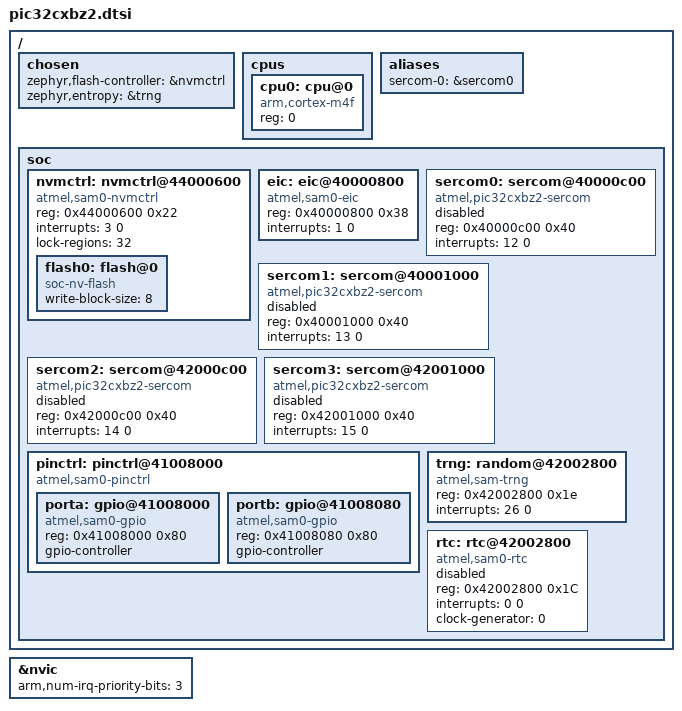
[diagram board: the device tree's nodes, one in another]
/*
 * Copyright (c) 2024 Microchip
 *
 * SPDX-License-Identifier: Apache-2.0
 */

#include <arm/armv7-m.dtsi>
#include <zephyr/dt-bindings/adc/adc.h>
#include <zephyr/dt-bindings/gpio/gpio.h>
#include <zephyr/dt-bindings/i2c/i2c.h>
#include <zephyr/dt-bindings/pwm/pwm.h>

/ {
	chosen {
		zephyr,flash-controller = &nvmctrl;
	};

	cpus {
		#address-cells = <1>;
		#size-cells = <0>;

		cpu0: cpu@0 {
			device_type = "cpu";
			compatible = "arm,cortex-m4f";
			reg = <0>;
			#address-cells = <1>;
			#size-cells = <1>;

			/*mpu: mpu@e000ed90 {
				compatible = "arm,armv7m-mpu";
				reg = <0xe000ed90 0x40>;
			};*/
		};
	};

	aliases {
		/*adc-0 = &adc0;
		

		port-a = &porta;
		port-b = &portb;*/

		sercom-0 = &sercom0;
		/*sercom-1 = &sercom1;
		sercom-2 = &sercom2;
		sercom-3 = &sercom3;

		tc-0 = &tc0;
		tc-2 = &tc2;

		tcc-0 = &tcc0;
		tcc-1 = &tcc1;
		tcc-2 = &tcc2;

		watchdog0 = &wdog;*/
	};

	chosen {
		zephyr,entropy = &trng;
	};

	soc {
		/*sram0: memory@20000000 {
			compatible = "mmio-sram";
			reg = <0x20000000 0x20000>;
		};*/

		/*backup0: memory@44014000 {44014000
			compatible = "mmio-sram";
			reg = <0x444014000 0x2000>;
		};*/

		/*id: device_id@8061fc {
			compatible = "atmel,sam0-id";
			reg =	<0x008061FC 0x4>,
				<0x00806010 0x4>,
				<0x00806014 0x4>,
				<0x00806018 0x4>;
		};*/


		nvmctrl: nvmctrl@44000600  {
			compatible = "atmel,sam0-nvmctrl";
			reg = <0x44000600 0x22>;
			interrupts = <3 0>;
			lock-regions = <32>;

			#address-cells = <1>;
			#size-cells = <1>;

			flash0: flash@0 {
				compatible = "soc-nv-flash";
				write-block-size = <8>;
			};
		};
/*
		dmac: dmac@41004000 {
			compatible = "atmel,sam0-dmac";
			reg = <0x41004000 0x50>;
			interrupts = <6 0>, <7 0>;
			#dma-cells = <2>;
		};
*/
		eic: eic@40000800 {
			compatible = "atmel,sam0-eic";
			reg = <0x40000800 0x38>;
			interrupts = <1 0>;
		};
		
/*
		pinmux_a: pinmux@41008000 {
			compatible = "atmel,sam0-pinmux";
			reg = <0x41008000 0x80>;
		};

		pinmux_b: pinmux@41008080 {
			compatible = "atmel,sam0-pinmux";
			reg = <0x41008080 0x80>;
		};

		pinmux_c: pinmux@41008100 {
			compatible = "atmel,sam0-pinmux";
			reg = <0x41008100 0x80>;
		};

		pinmux_d: pinmux@41008180 {
			compatible = "atmel,sam0-pinmux";
			reg = <0x41008180 0x80>;
		};

		wdog: watchdog@44000500{
			compatible = "atmel,sam0-watchdog";
			reg = <0x44000500 13>;
			interrupts = <140 0>;    
		};
*/

		sercom0: sercom@40000c00 {
			compatible = "atmel,pic32cxbz2-sercom";
			reg = <0x40000c00 0x40>;
			interrupts = <12 0>;
			status = "disabled";
		};
		
		sercom1: sercom@40001000 {
			compatible = "atmel,pic32cxbz2-sercom";
			reg = <0x40001000 0x40>;
			interrupts = <13 0>;
			status = "disabled";
		};

		sercom2: sercom@42000c00 {
			compatible = "atmel,pic32cxbz2-sercom";
			reg = <0x42000c00 0x40>;
			interrupts = <14 0>;
			status = "disabled";
		};

		sercom3: sercom@42001000 {
			compatible = "atmel,pic32cxbz2-sercom";
			reg = <0x42001000 0x40>;
			interrupts = <15 0>;
			status = "disabled";
		};




		pinctrl: pinctrl@41008000 {
			compatible = "atmel,sam0-pinctrl";
			#address-cells = <1>;
			#size-cells = <1>;
			ranges = <0x41008000 0x41008000 0x200>;

			porta: gpio@41008000 {
				compatible = "atmel,sam0-gpio";
				reg = <0x41008000 0x80>;
				gpio-controller;
				#gpio-cells = <2>;
				#atmel,pin-cells = <2>;
			};

			portb: gpio@41008080 {
				compatible = "atmel,sam0-gpio";
				reg = <0x41008080 0x80>;
				gpio-controller;
				#gpio-cells = <2>;
				#atmel,pin-cells = <2>;
			};
		};
		
		

		trng: random@42002800 {
			compatible = "atmel,sam-trng";
			reg = <0x42002800 0x1e>;
			interrupts = <26 0>;
		};

		rtc: rtc@42002800 {
			compatible = "atmel,sam0-rtc";
			reg = <0x42002800 0x1C>;
			interrupts = <0 0>;
			clock-generator = <0>;
			status = "disabled";
		};
/*
		adc0: adc@43001c00 {
			compatible = "atmel,sam0-adc";
			reg = <0x43001C00 0x4A>;
			interrupts = <23 0>;

			gclk = <2>;
			prescaler = <4>;
			#io-channel-cells = <1>;
			clocks = <&gclk 40>, <&mclk 0x20 7>;
			clock-names = "GCLK", "MCLK";
			calib-offset = <0>;
		};

		tc0: tc@40001400 {
			compatible = "atmel,sam0-tc32";
			reg = <0x40001400 0x34>;
			interrupts = <19 0>;
			clocks = <&gclk 9>, <&mclk 0x14 14>;
			clock-names = "GCLK", "MCLK";
		};

		tc1: tc@40001800 {
			compatible = "atmel,sam0-tc32";
			reg = <0x40001800 0x34>;
			interrupts = <19 0>;
			clocks = <&gclk 9>, <&mclk 0x14 14>;
			clock-names = "GCLK", "MCLK";
		};

		tc2: tc@40001C00 {
			compatible = "atmel,sam0-tc32";
			reg = <0x40001C00 0x34>;
			interrupts = <20 0>;
			clocks = <&gclk 26>, <&mclk 0x18 13>;
			clock-names = "GCLK", "MCLK";
		};

		tc4: tc@40002000 {
			compatible = "atmel,sam0-tc32";
			reg = <0x40002000 0x34>;
			interrupts = <21 0>;
			clocks = <&gclk 30>, <&mclk 0x1c 5>;
			clock-names = "GCLK", "MCLK";
		};

		tcc0: tcc@40002400 {
			compatible = "atmel,sam0-tcc";
			reg = <0x40002400 0x2000>;
			interrupts = <16 0>;
			clocks = <&gclk 25>, <&mclk 0x18 11>;
			clock-names = "GCLK", "MCLK";
			channels = <6>;
			counter-size = <24>;
		};

		tcc1: tcc@40002800 {
			compatible = "atmel,sam0-tcc";
			reg = <0x40002800 0x2000>;
			interrupts = <17 0>;
			clocks = <&gclk 25>, <&mclk 0x18 12>;
			clock-names = "GCLK", "MCLK";
			channels = <4>;
			counter-size = <24>;
		};

		tcc2: tcc@40002C00 {
			compatible = "atmel,sam0-tcc";
			reg = <0x40002C00 0x400>;
			interrupts = <18 0>;
			clocks = <&gclk 29>, <&mclk 0x1c 3>;
			clock-names = "GCLK", "MCLK";
			channels = <3>;
			counter-size = <16>;
		};
*/		
	};
};

&nvic {
	arm,num-irq-priority-bits = <3>;
};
